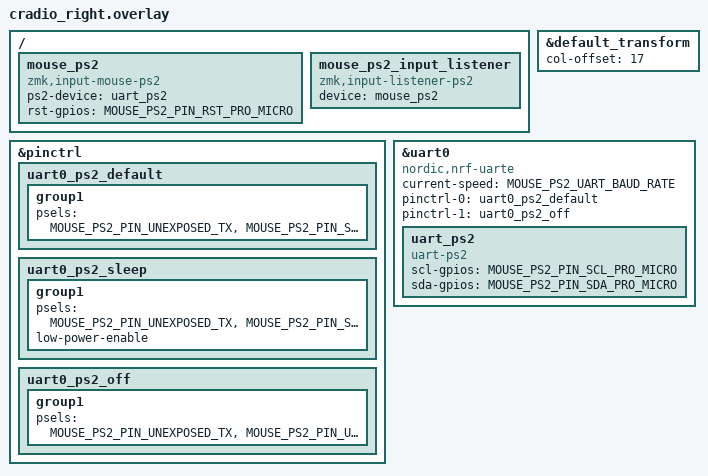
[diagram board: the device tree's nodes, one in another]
/*
 * Cradio right half with PS/2 TrackPoint support
 *
 * Copyright (c) 2020 The ZMK Contributors
 *
 * SPDX-License-Identifier: MIT
 */

#include "cradio.dtsi"

&default_transform {
    col-offset = <17>;
};

/*
 * PS/2 Mouse / Trackpoint - User Configuration
 * Enable PS/2 drivers on this side of the keyboard.
 * It MUST be the central half.
 */

// Pick the PS/2 driver (UART recommended for nRF52)
#define MOUSE_PS2_DRIVER_UART

// Standard Corne pins for PS/2 TrackPoint:
// D16 (SCL), D10 (SDA), D9 (RST/Reset circuit)
#define MOUSE_PS2_PIN_SCL_PRO_MICRO <&pro_micro 16 GPIO_ACTIVE_HIGH>
#define MOUSE_PS2_PIN_SDA_PRO_MICRO <&pro_micro 10 GPIO_ACTIVE_HIGH>
#define MOUSE_PS2_PIN_RST_PRO_MICRO <&pro_micro 9 GPIO_ACTIVE_HIGH>

// UART pinctrl notation for SDA pin
#define MOUSE_PS2_PIN_SDA_PINCTRL <NRF_PSEL(UART_RX, 0, 9)>

// Standard BAUD rate for TrackPoints (14400)
#define MOUSE_PS2_UART_BAUD_RATE <14400>

// Unexposed UART pins (nRF52 specific)
#define MOUSE_PS2_PIN_UNEXPOSED_TX <NRF_PSEL(UART_TX, 0, 27)>
#define MOUSE_PS2_PIN_UNEXPOSED_RX <NRF_PSEL(UART_RX, 0, 28)>

// Marker for keymap conditional compilation
#define MOUSE_PS2_DT_PRESENT

&pinctrl {
    uart0_ps2_default: uart0_ps2_default {
        group1 {
            psels = MOUSE_PS2_PIN_UNEXPOSED_TX,
                    MOUSE_PS2_PIN_SDA_PINCTRL;
        };
    };

    uart0_ps2_sleep: uart0_ps2_sleep {
        group1 {
            psels = MOUSE_PS2_PIN_UNEXPOSED_TX,
                    MOUSE_PS2_PIN_SDA_PINCTRL;
            low-power-enable;
        };
    };

    uart0_ps2_off: uart0_ps2_off {
        group1 {
            psels = MOUSE_PS2_PIN_UNEXPOSED_TX,
                    MOUSE_PS2_PIN_UNEXPOSED_RX;
        };
    };
};


#ifdef MOUSE_PS2_DRIVER_UART

    &uart0 {
        status = "disabled";
        compatible = "nordic,nrf-uarte";

        current-speed = MOUSE_PS2_UART_BAUD_RATE;
        pinctrl-0 = <&uart0_ps2_default>;
        pinctrl-1 = <&uart0_ps2_off>;

        pinctrl-names = "default", "sleep";

        uart_ps2: uart_ps2 {
            status = "disabled";
            compatible = "uart-ps2";
            scl-gpios = MOUSE_PS2_PIN_SCL_PRO_MICRO;
            sda-gpios = MOUSE_PS2_PIN_SDA_PRO_MICRO;
        };
    };

#else

    / {
        gpio_ps2: gpio_ps2 {
            status = "disabled";

            compatible = "gpio-ps2";
            scl-gpios = MOUSE_PS2_PIN_SCL_PRO_MICRO;
            sda-gpios = MOUSE_PS2_PIN_SDA_PRO_MICRO;
        };
    };

#endif


/ {
    mouse_ps2: mouse_ps2 {
        status = "disabled";
        compatible = "zmk,input-mouse-ps2";

#ifdef MOUSE_PS2_DRIVER_UART
        ps2-device = <&uart_ps2>;
#else
        ps2-device = <&gpio_ps2>;
#endif

#ifdef MOUSE_PS2_PIN_RST_PRO_MICRO
        rst-gpios = MOUSE_PS2_PIN_RST_PRO_MICRO;
#endif
    };

    mouse_ps2_input_listener: mouse_ps2_input_listener {
        compatible = "zmk,input-listener-ps2";
        status = "disabled";

        device = <&mouse_ps2>;
    };
};

/*
 * Enable PS/2 devices (only on side with TrackPoint)
 */
#ifdef MOUSE_PS2_DT_PRESENT
    &mouse_ps2 {
        status = "okay";
    };

    &mouse_ps2_input_listener {
        status = "okay";
    };

    #ifdef MOUSE_PS2_DRIVER_UART
        &uart0 {
            status = "okay";
        };

        &uart_ps2 {
            status = "okay";
        };
    #else
        &gpio_ps2 {
            status = "okay";
        };
    #endif
#endif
